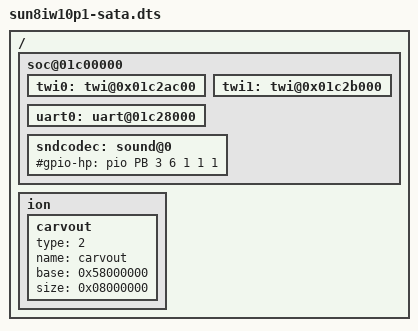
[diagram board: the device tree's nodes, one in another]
/*
 * Allwinner Technology CO., Ltd. sun8iw10p1 perf1 sata board.
 *
 */

/dts-v1/;

/memreserve/ 0x58000000 0x08000000; /* ion carvout heap revserve  : [0x58000000~0x60000000], size = 128M  */

#include "sun8iw10p1.dtsi"

/{

	soc@01c00000 {
		twi0: twi@0x01c2ac00{
			status = "okay";
		};

		twi1: twi@0x01c2b000{
			status = "okay";
		};

		uart0: uart@01c28000 {
			status = "okay";
		};

		sndcodec:sound@0{
			#gpio-hp = <&pio PB 3 6 1 1 1 >;
		};
	};

	ion {
		carvout{
			type = <2>;
			name = "carvout";
			base = <0x58000000>;
			size = <0x08000000>;
		};
	};
};
